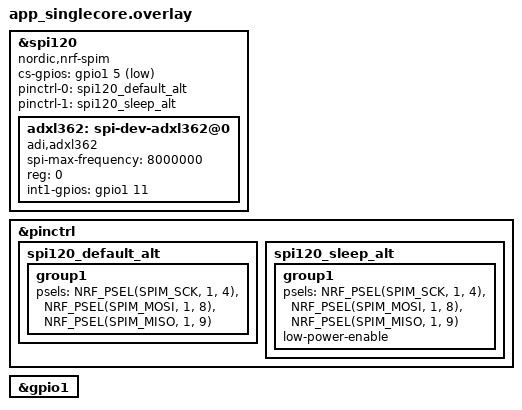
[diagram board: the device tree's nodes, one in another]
/*
 * Copyright (c) 2023 Nordic Semiconductor ASA
 *
 * SPDX-License-Identifier: LicenseRef-Nordic-5-Clause
 */

#include "app.overlay"


&spi120 {
	compatible = "nordic,nrf-spim";
	status = "okay";
	cs-gpios = <&gpio1 5 GPIO_ACTIVE_LOW>;

	pinctrl-0 = <&spi120_default_alt>;
	pinctrl-1 = <&spi120_sleep_alt>;
	pinctrl-names = "default", "sleep";
	adxl362: spi-dev-adxl362@0 {
		compatible = "adi,adxl362";
		spi-max-frequency = <8000000>;
		reg = <0>;
		int1-gpios = <&gpio1 11 0>;
	};
};

&pinctrl {
	spi120_default_alt: spi120_default_alt {
		group1 {
			psels = <NRF_PSEL(SPIM_SCK, 1, 4)>,
				<NRF_PSEL(SPIM_MOSI, 1, 8)>,
				<NRF_PSEL(SPIM_MISO, 1, 9)>;
		};
	};

	spi120_sleep_alt: spi120_sleep_alt {
		group1 {
			psels = <NRF_PSEL(SPIM_SCK, 1, 4)>,
				<NRF_PSEL(SPIM_MOSI, 1, 8)>,
				<NRF_PSEL(SPIM_MISO, 1, 9)>;
			low-power-enable;
		};
	};
};

&gpio1 {
	status = "okay";
};

// /delete-node/ &cpuapp_rx_partitions;
// /delete-node/ &cpuapp_rw_partitions;

// &mram1x {
// 	cpuapp_rx_partitions: cpuapp-rx-partitions {
// 		compatible = "nordic,owned-partitions", "fixed-partitions";
// 		status = "disabled";
// 		perm-read;
// 		perm-execute;
// 		perm-secure;
// 		#address-cells = <1>;
// 		#size-cells = <1>;

// 		cpuapp_slot0_partition: partition@100000 {
// 			reg = <0x100000 DT_SIZE_K(512)>;
// 		};

// 		cpuppr_code_partition: partition@180000 {
// 			reg = <0x180000 DT_SIZE_K(64)>;
// 		};
// 	};

// 	cpuapp_rw_partitions: cpuapp-rw-partitions {
// 		compatible = "nordic,owned-partitions", "fixed-partitions";
// 		status = "disabled";
// 		perm-read;
// 		perm-write;
// 		perm-secure;
// 		#address-cells = <1>;
// 		#size-cells = <1>;

// 		storage_partition: partition@190000 {
// 			reg = <0x190000 DT_SIZE_K(24)>;
// 		};
// 	};
// };
